# ionuc505 register map
Registers are 32-bit, access not given, no defined reset value unless marked. A register's access mark holds for its fields unless they carry their own. Addresses are absolute; registers are grouped by the start of their names; [hi:lo] are bit positions; {n}, {i} and the like mark numbered series; 'fields as' and 'values as' point back to an identical list.

## I2C0
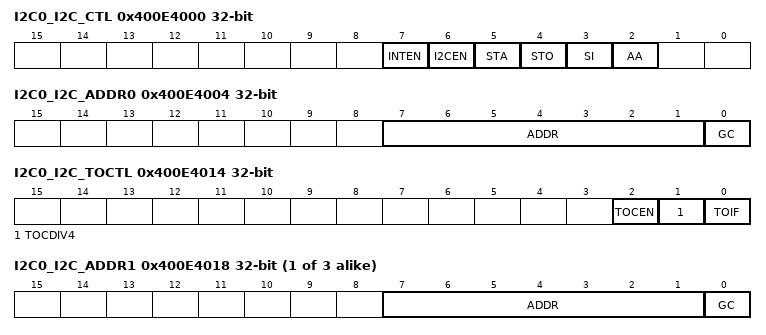
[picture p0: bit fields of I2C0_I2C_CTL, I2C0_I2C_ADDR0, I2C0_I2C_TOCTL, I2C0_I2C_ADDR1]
0x400E4000 I2C0_I2C_CTL
  [7] INTEN, [6] I2CEN, [5] STA, [4] STO, [3] SI, [2] AA
0x400E4004 I2C0_I2C_ADDR0
  [7:1] ADDR, [0] GC
0x400E4008 I2C0_I2C_DAT
  [7:0] DAT
0x400E400C I2C0_I2C_STATUS
  [7:0] STATUS
0x400E4010 I2C0_I2C_CLKDIV
  [7:0] DIVIDER
0x400E4014 I2C0_I2C_TOCTL
  [2] TOCEN, [1] TOCDIV4, [0] TOIF
{0x400E4014+4i} I2C0_I2C_ADDR{i} (i=1..3)
  [7:1] ADDR, [0] GC
{0x400E4024+4i} I2C0_I2C_ADDRMSK{i} (i=0..3)
  [7:1] ADDRMSK
0x400E403C I2C0_I2C_WKCTL
  [0] WKEN
0x400E4040 I2C0_I2C_WKSTS
  [0] WKIF

## I2C1
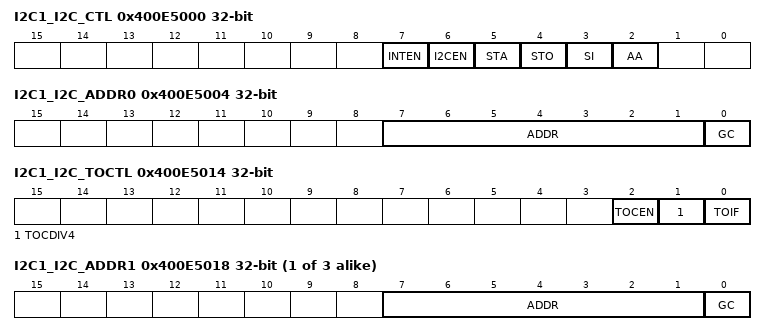
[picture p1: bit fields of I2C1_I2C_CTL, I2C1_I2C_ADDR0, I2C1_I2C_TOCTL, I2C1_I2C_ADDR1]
0x400E5000 I2C1_I2C_CTL
  [7] INTEN, [6] I2CEN, [5] STA, [4] STO, [3] SI, [2] AA
0x400E5004 I2C1_I2C_ADDR0
  [7:1] ADDR, [0] GC
0x400E5008 I2C1_I2C_DAT
  [7:0] DAT
0x400E500C I2C1_I2C_STATUS
  [7:0] STATUS
0x400E5010 I2C1_I2C_CLKDIV
  [7:0] DIVIDER
0x400E5014 I2C1_I2C_TOCTL
  [2] TOCEN, [1] TOCDIV4, [0] TOIF
{0x400E5014+4i} I2C1_I2C_ADDR{i} (i=1..3)
  [7:1] ADDR, [0] GC
{0x400E5024+4i} I2C1_I2C_ADDRMSK{i} (i=0..3)
  [7:1] ADDRMSK
0x400E503C I2C1_I2C_WKCTL
  [0] WKEN
0x400E5040 I2C1_I2C_WKSTS
  [0] WKIF

## SPI0
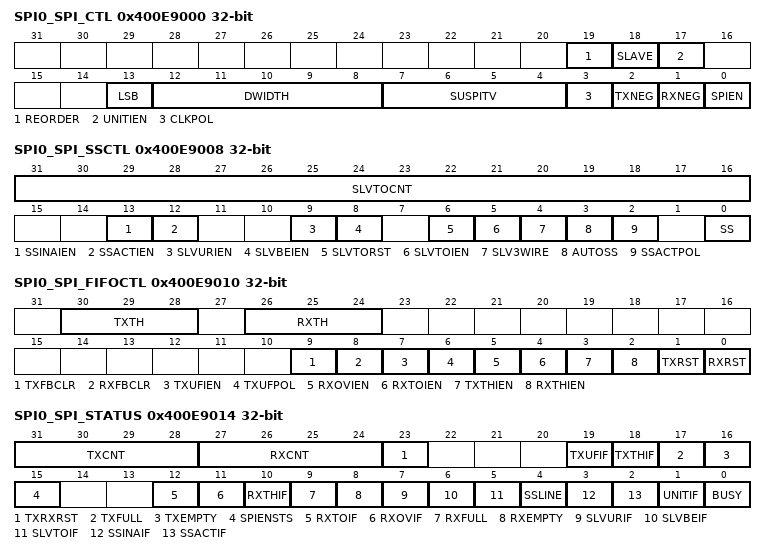
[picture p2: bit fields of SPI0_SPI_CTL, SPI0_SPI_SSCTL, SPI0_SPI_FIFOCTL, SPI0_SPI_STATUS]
0x400E9000 SPI0_SPI_CTL
  [19] REORDER, [18] SLAVE, [17] UNITIEN, [13] LSB, [12:8] DWIDTH, [7:4] SUSPITV, [3] CLKPOL, [2] TXNEG, [1] RXNEG, [0] SPIEN
0x400E9004 SPI0_SPI_CLKDIV
  [7:0] DIVIDER
0x400E9008 SPI0_SPI_SSCTL
  [31:16] SLVTOCNT, [13] SSINAIEN, [12] SSACTIEN, [9] SLVURIEN, [8] SLVBEIEN, [6] SLVTORST, [5] SLVTOIEN, [4] SLV3WIRE, [3] AUTOSS, [2] SSACTPOL, [0] SS
0x400E9010 SPI0_SPI_FIFOCTL
  [30:28] TXTH, [26:24] RXTH, [9] TXFBCLR, [8] RXFBCLR, [7] TXUFIEN, [6] TXUFPOL, [5] RXOVIEN, [4] RXTOIEN, [3] TXTHIEN, [2] RXTHIEN, [1] TXRST, [0] RXRST
0x400E9014 SPI0_SPI_STATUS
  [31:28] TXCNT, [27:24] RXCNT, [23] TXRXRST, [19] TXUFIF, [18] TXTHIF, [17] TXFULL, [16] TXEMPTY, [15] SPIENSTS, [12] RXTOIF, [11] RXOVIF, [10] RXTHIF, [9] RXFULL, [8] RXEMPTY, [7] SLVURIF, [6] SLVBEIF, [5] SLVTOIF, [4] SSLINE, [3] SSINAIF, [2] SSACTIF, [1] UNITIF, [0] BUSY
0x400E9020 SPI0_SPI_TX
0x400E9030 SPI0_SPI_RX

## SPI1
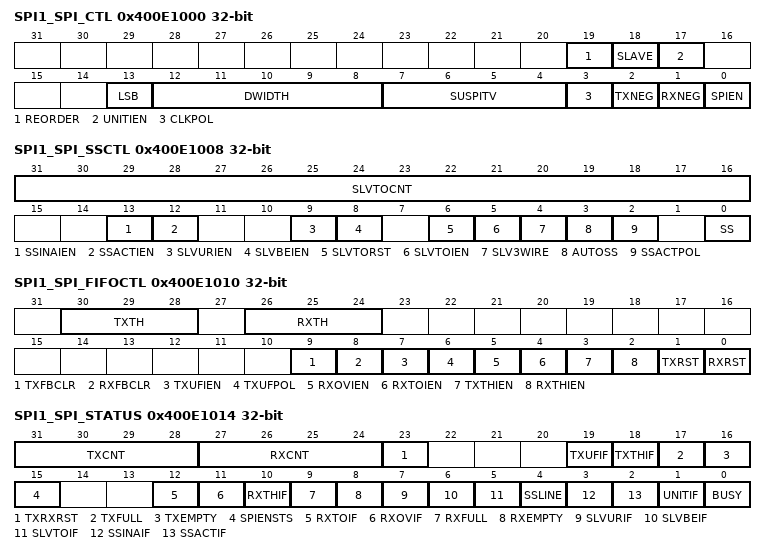
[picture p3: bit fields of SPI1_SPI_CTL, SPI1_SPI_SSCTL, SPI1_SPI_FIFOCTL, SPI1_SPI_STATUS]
0x400E1000 SPI1_SPI_CTL
  [19] REORDER, [18] SLAVE, [17] UNITIEN, [13] LSB, [12:8] DWIDTH, [7:4] SUSPITV, [3] CLKPOL, [2] TXNEG, [1] RXNEG, [0] SPIEN
0x400E1004 SPI1_SPI_CLKDIV
  [7:0] DIVIDER
0x400E1008 SPI1_SPI_SSCTL
  [31:16] SLVTOCNT, [13] SSINAIEN, [12] SSACTIEN, [9] SLVURIEN, [8] SLVBEIEN, [6] SLVTORST, [5] SLVTOIEN, [4] SLV3WIRE, [3] AUTOSS, [2] SSACTPOL, [0] SS
0x400E1010 SPI1_SPI_FIFOCTL
  [30:28] TXTH, [26:24] RXTH, [9] TXFBCLR, [8] RXFBCLR, [7] TXUFIEN, [6] TXUFPOL, [5] RXOVIEN, [4] RXTOIEN, [3] TXTHIEN, [2] RXTHIEN, [1] TXRST, [0] RXRST
0x400E1014 SPI1_SPI_STATUS
  [31:28] TXCNT, [27:24] RXCNT, [23] TXRXRST, [19] TXUFIF, [18] TXTHIF, [17] TXFULL, [16] TXEMPTY, [15] SPIENSTS, [12] RXTOIF, [11] RXOVIF, [10] RXTHIF, [9] RXFULL, [8] RXEMPTY, [7] SLVURIF, [6] SLVBEIF, [5] SLVTOIF, [4] SSLINE, [3] SSINAIF, [2] SSACTIF, [1] UNITIF, [0] BUSY
0x400E1020 SPI1_SPI_TX
0x400E1030 SPI1_SPI_RX

## SPIM
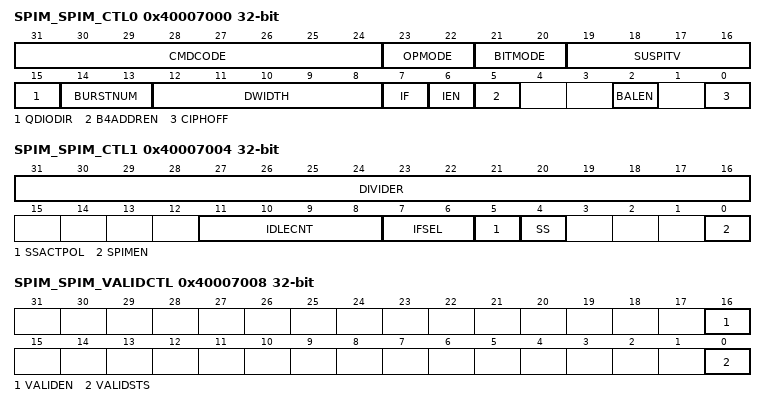
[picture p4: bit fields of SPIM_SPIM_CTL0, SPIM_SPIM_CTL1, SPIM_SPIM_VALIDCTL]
0x40007000 SPIM_SPIM_CTL0
  [31:24] CMDCODE, [23:22] OPMODE, [21:20] BITMODE, [19:16] SUSPITV, [15] QDIODIR, [14:13] BURSTNUM, [12:8] DWIDTH, [7] IF, [6] IEN, [5] B4ADDREN, [2] BALEN, [0] CIPHOFF
0x40007004 SPIM_SPIM_CTL1
  [31:16] DIVIDER, [11:8] IDLECNT, [7:6] IFSEL, [5] SSACTPOL, [4] SS, [0] SPIMEN
0x40007008 SPIM_SPIM_VALIDCTL
  [16] VALIDEN, [0] VALIDSTS
{0x40007010+4i} SPIM_SPIM_RX{i} (i=0..3)
{0x40007020+4i} SPIM_SPIM_TX{i} (i=0..3)
0x40007030 SPIM_SPIM_SRAMADDR
0x40007034 SPIM_SPIM_DMATBCNT
  [23:0] CNT
0x40007038 SPIM_SPIM_FADDR

## I2S
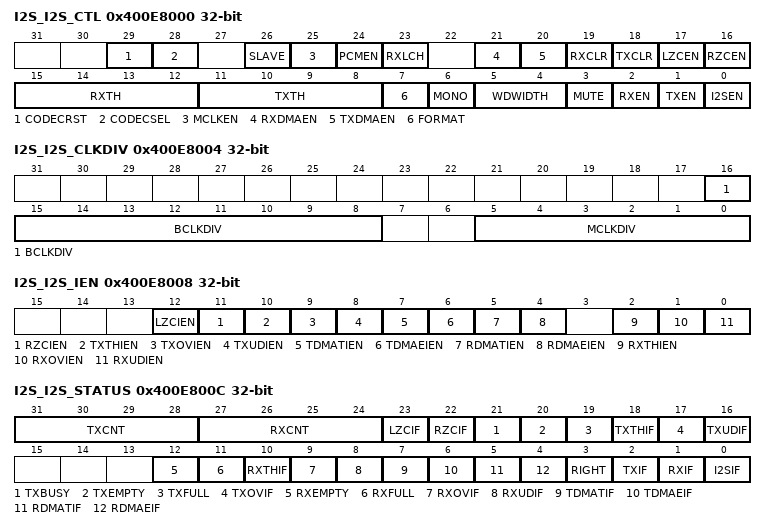
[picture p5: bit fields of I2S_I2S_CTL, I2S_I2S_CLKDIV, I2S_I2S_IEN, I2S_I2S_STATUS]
0x400E8000 I2S_I2S_CTL
  [29] CODECRST, [28] CODECSEL, [26] SLAVE, [25] MCLKEN, [24] PCMEN, [23] RXLCH, [21] RXDMAEN, [20] TXDMAEN, [19] RXCLR, [18] TXCLR, [17] LZCEN, [16] RZCEN, [15:12] RXTH, [11:8] TXTH, [7] FORMAT, [6] MONO, [5:4] WDWIDTH, [3] MUTE, [2] RXEN, [1] TXEN, [0] I2SEN
0x400E8004 I2S_I2S_CLKDIV
  [16:8] BCLKDIV, [5:0] MCLKDIV
0x400E8008 I2S_I2S_IEN
  [12] LZCIEN, [11] RZCIEN, [10] TXTHIEN, [9] TXOVIEN, [8] TXUDIEN, [7] TDMATIEN, [6] TDMAEIEN, [5] RDMATIEN, [4] RDMAEIEN, [2] RXTHIEN, [1] RXOVIEN, [0] RXUDIEN
0x400E800C I2S_I2S_STATUS
  [31:28] TXCNT, [27:24] RXCNT, [23] LZCIF, [22] RZCIF, [21] TXBUSY, [20] TXEMPTY, [19] TXFULL, [18] TXTHIF, [17] TXOVIF, [16] TXUDIF, [12] RXEMPTY, [11] RXFULL, [10] RXTHIF, [9] RXOVIF, [8] RXUDIF, [7] TDMATIF, [6] TDMAEIF, [5] RDMATIF, [4] RDMAEIF, [3] RIGHT, [2] TXIF, [1] RXIF, [0] I2SIF
0x400E8010 I2S_I2S_TX
0x400E8014 I2S_I2S_RX
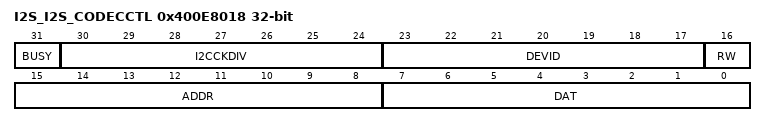
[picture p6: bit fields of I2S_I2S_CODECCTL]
0x400E8018 I2S_I2S_CODECCTL
  [31] BUSY, [30:24] I2CCKDIV, [23:17] DEVID, [16] RW, [15:8] ADDR, [7:0] DAT
0x400E8020 I2S_I2S_TXSTADDR
0x400E8024 I2S_I2S_TXTHADDR
0x400E8028 I2S_I2S_TXEADDR
0x400E802C I2S_I2S_TXCADDR
0x400E8030 I2S_I2S_RXSTADDR
0x400E8034 I2S_I2S_RXTHADDR
0x400E8038 I2S_I2S_RXEADDR
0x400E803C I2S_I2S_RXCADDR
0x400E8040 I2S_I2S_RXAVGCTL
  [3:0] WINSEL
0x400E8044 I2S_I2S_RXLCHAVG
0x400E8048 I2S_I2S_RXRCHAVG

## USBH
0x4000B000 USBH_HCREVISION
  [7:0] REV
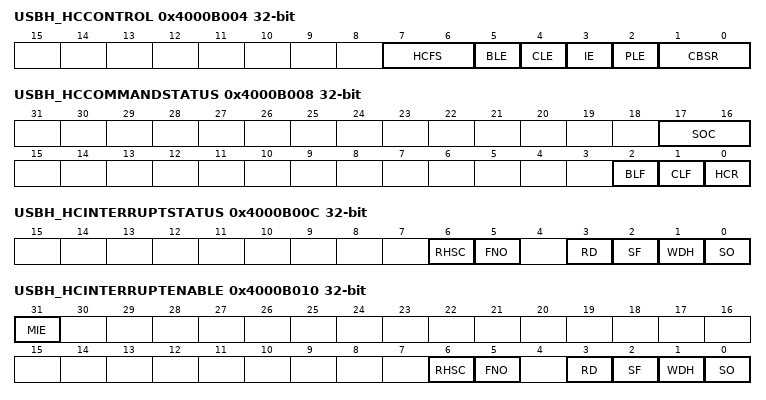
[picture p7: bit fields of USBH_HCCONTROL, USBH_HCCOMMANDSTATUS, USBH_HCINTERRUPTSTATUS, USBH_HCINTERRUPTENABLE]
0x4000B004 USBH_HCCONTROL
  [7:6] HCFS, [5] BLE, [4] CLE, [3] IE, [2] PLE, [1:0] CBSR
0x4000B008 USBH_HCCOMMANDSTATUS
  [17:16] SOC, [2] BLF, [1] CLF, [0] HCR
0x4000B00C USBH_HCINTERRUPTSTATUS
  [6] RHSC, [5] FNO, [3] RD, [2] SF, [1] WDH, [0] SO
0x4000B010 USBH_HCINTERRUPTENABLE
  [31] MIE, [6] RHSC, [5] FNO, [3] RD, [2] SF, [1] WDH, [0] SO
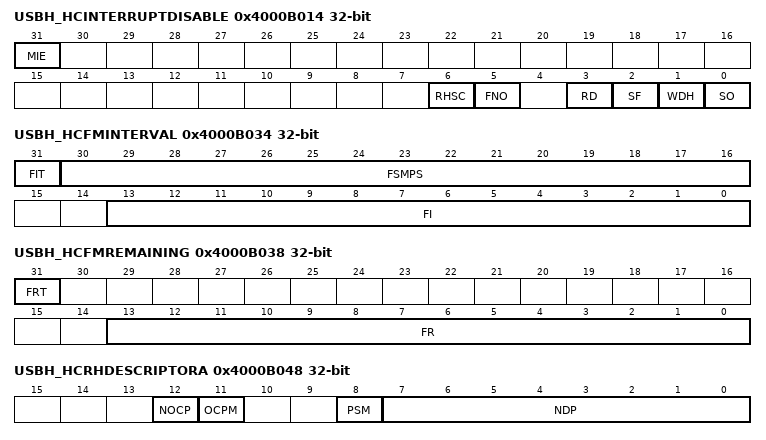
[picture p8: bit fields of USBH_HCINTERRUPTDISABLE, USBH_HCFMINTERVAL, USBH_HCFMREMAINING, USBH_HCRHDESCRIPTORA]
0x4000B014 USBH_HCINTERRUPTDISABLE
  [31] MIE, [6] RHSC, [5] FNO, [3] RD, [2] SF, [1] WDH, [0] SO
0x4000B018 USBH_HCHCCA
  [31:8] HCCA
0x4000B01C USBH_HCPERIODCURRENTED
  [31:4] PCED
0x4000B020 USBH_HCCONTROLHEADED
  [31:4] CHED
0x4000B024 USBH_HCCONTROLCURRENTED
  [31:4] CCED
0x4000B028 USBH_HCBULKHEADED
  [31:4] BHED
0x4000B02C USBH_HCBULKCURRENTED
  [31:4] BCED
0x4000B030 USBH_HCDONEHEAD
  [31:4] DH
0x4000B034 USBH_HCFMINTERVAL
  [31] FIT, [30:16] FSMPS, [13:0] FI
0x4000B038 USBH_HCFMREMAINING
  [31] FRT, [13:0] FR
0x4000B03C USBH_HCFMNUMBER
  [15:0] FN
0x4000B040 USBH_HCPERIODICSTART
  [13:0] PS
0x4000B044 USBH_HCLSTHRESHOLD
  [11:0] LST
0x4000B048 USBH_HCRHDESCRIPTORA
  [12] NOCP, [11] OCPM, [8] PSM, [7:0] NDP
0x4000B04C USBH_HCRHDESCRIPTORB
  [31:16] PPCM
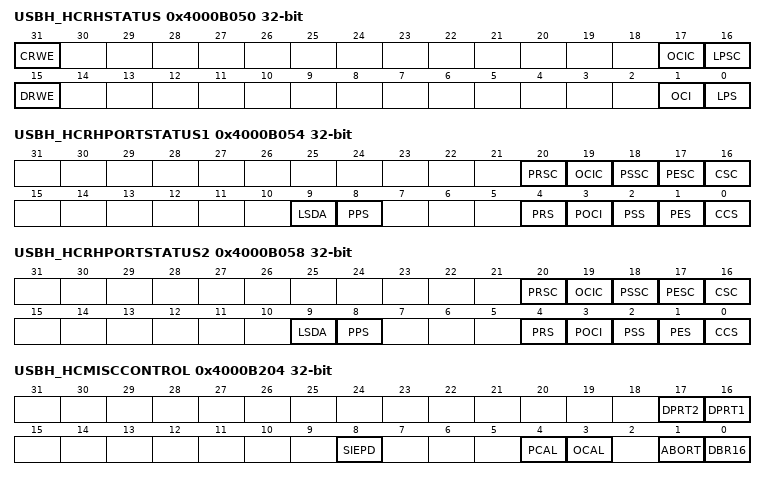
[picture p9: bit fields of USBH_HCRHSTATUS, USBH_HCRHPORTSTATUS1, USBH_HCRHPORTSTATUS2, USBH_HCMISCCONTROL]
0x4000B050 USBH_HCRHSTATUS
  [31] CRWE, [17] OCIC, [16] LPSC, [15] DRWE, [1] OCI, [0] LPS
0x4000B054 USBH_HCRHPORTSTATUS1
  [20] PRSC, [19] OCIC, [18] PSSC, [17] PESC, [16] CSC, [9] LSDA, [8] PPS, [4] PRS, [3] POCI, [2] PSS, [1] PES, [0] CCS
0x4000B058 USBH_HCRHPORTSTATUS2
  fields as USBH_HCRHPORTSTATUS1
0x4000B200 USBH_HCPHYCONTROL
  [27] STBYEN
0x4000B204 USBH_HCMISCCONTROL
  [17] DPRT2, [16] DPRT1, [8] SIEPD, [4] PCAL, [3] OCAL, [1] ABORT, [0] DBR16

## SDH
{0x4000A000+4i} SDH_SDH_FB_{i} (i=0..31)
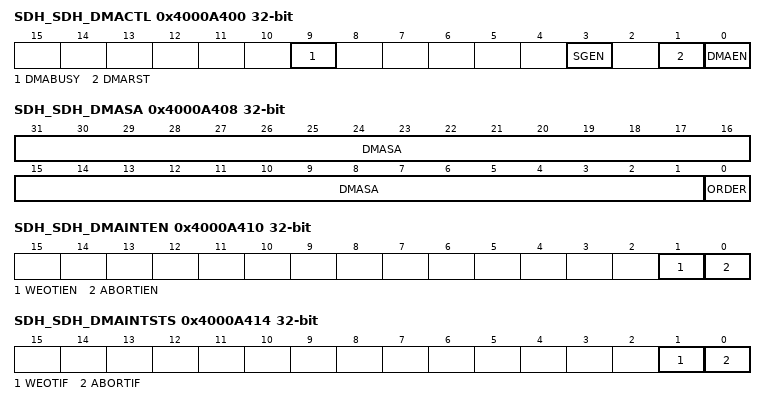
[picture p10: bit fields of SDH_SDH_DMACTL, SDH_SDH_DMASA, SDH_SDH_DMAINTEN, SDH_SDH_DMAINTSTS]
0x4000A400 SDH_SDH_DMACTL
  [9] DMABUSY, [3] SGEN, [1] DMARST, [0] DMAEN
0x4000A408 SDH_SDH_DMASA
  [31:1] DMASA, [0] ORDER
0x4000A40C SDH_SDH_DMABCNT
  [25:0] BCNT
0x4000A410 SDH_SDH_DMAINTEN
  [1] WEOTIEN, [0] ABORTIEN
0x4000A414 SDH_SDH_DMAINTSTS
  [1] WEOTIF, [0] ABORTIF
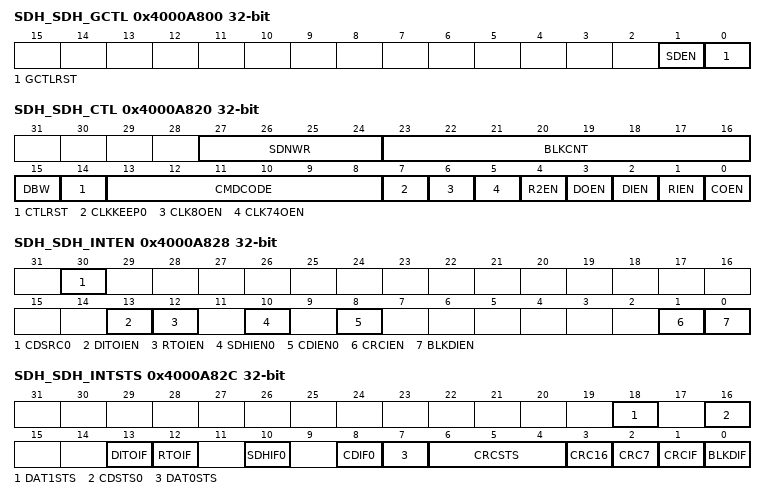
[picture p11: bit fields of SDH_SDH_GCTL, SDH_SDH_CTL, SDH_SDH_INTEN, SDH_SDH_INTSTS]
0x4000A800 SDH_SDH_GCTL
  [1] SDEN, [0] GCTLRST
0x4000A804 SDH_SDH_GINTEN
  [0] DTAIEN
0x4000A808 SDH_SDH_GINTSTS
  [0] DTAIF
0x4000A820 SDH_SDH_CTL
  [27:24] SDNWR, [23:16] BLKCNT, [15] DBW, [14] CTLRST, [13:8] CMDCODE, [7] CLKKEEP0, [6] CLK8OEN, [5] CLK74OEN, [4] R2EN, [3] DOEN, [2] DIEN, [1] RIEN, [0] COEN
0x4000A824 SDH_SDH_CMDARG
0x4000A828 SDH_SDH_INTEN
  [30] CDSRC0, [13] DITOIEN, [12] RTOIEN, [10] SDHIEN0, [8] CDIEN0, [1] CRCIEN, [0] BLKDIEN
0x4000A82C SDH_SDH_INTSTS
  [18] DAT1STS, [16] CDSTS0, [13] DITOIF, [12] RTOIF, [10] SDHIF0, [8] CDIF0, [7] DAT0STS, [6:4] CRCSTS, [3] CRC16, [2] CRC7, [1] CRCIF, [0] BLKDIF
0x4000A830 SDH_SDH_RESP0
0x4000A834 SDH_SDH_RESP1
  [7:0] RESPTK1
0x4000A838 SDH_SDH_BLEN
  [10:0] BLKLEN
0x4000A83C SDH_SDH_TOUT
  [23:0] TOUT

## ADC
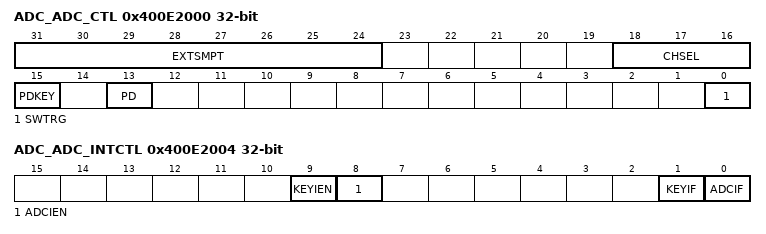
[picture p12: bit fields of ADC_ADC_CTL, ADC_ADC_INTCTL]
0x400E2000 ADC_ADC_CTL
  [31:24] EXTSMPT, [18:16] CHSEL, [15] PDKEY, [13] PD, [0] SWTRG
0x400E2004 ADC_ADC_INTCTL
  [9] KEYIEN, [8] ADCIEN, [1] KEYIF, [0] ADCIF
0x400E2008 ADC_ADC_DAT
  [11:0] RESULT
